# ATtiny2313A register map
Vendor: Atmel; File version: 1.0
CPU: other r0p0, little endian, no MPU, no FPU, 4 interrupt priority bits
Registers are 8-bit, read-write, reset 0x0 unless marked. A register's access mark holds for its fields unless they carry their own. Offsets are from the block's base; lines under a group give offsets from that group; [hi:lo] are bit positions; {n}, {i} and the like mark numbered series; 'fields as' and 'values as' point back to an identical list; <NAME> marks a mode.

## Memory map
0x00000000 FUSE size 0x3 — Fuses
0x00000000 LOCKBIT size 0x1 — Lockbits
0x00000021 AC blocks up to offset 0x8 — Analog Comparator
0x00000022 USART blocks up to offset 0xB
0x00000024 EXINT blocks up to offset 0x38 — External Interrupts
0x00000026 CPU blocks up to offset 0x38 — CPU Registers
0x0000002D USI size 0x3 — Universal Serial Interface
0x00000030 PORTD size 0x3 — I/O Port
0x00000036 PORTB size 0x3 — I/O Port
0x00000039 PORTA size 0x3 — I/O Port
0x0000003C EEPROM size 0x3
0x00000041 WDT size 0x1 — Watchdog Timer
0x00000042 TC1 blocks up to offset 0x18 — Timer/Counter, 16-bit
0x00000050 TC0 blocks up to offset 0xD — Timer/Counter, 8-bit

## Interrupts
0 RESET (CPU) — External Reset, Power-on Reset and Watchdog Reset
1 INT0 (CPU) — External Interrupt Request 0
2 INT1 (CPU) — External Interrupt Request 1
3 TIMER1_CAPT (CPU) — Timer/Counter1 Capture Event
4 TIMER1_COMPA (CPU) — Timer/Counter1 Compare Match A
5 TIMER1_OVF (CPU) — Timer/Counter1 Overflow
6 TIMER0_OVF (CPU) — Timer/Counter0 Overflow
7 USART_RX (CPU) — USART, Rx Complete
8 USART_UDRE (CPU) — USART Data Register Empty
9 USART_TX (CPU) — USART, Tx Complete
10 ANA_COMP (CPU) — Analog Comparator
11 PCINT_B (CPU) — Pin Change Interrupt Request B
12 TIMER1_COMPB (CPU)
13 TIMER0_COMPA (CPU)
14 TIMER0_COMPB (CPU)
15 USI_START (CPU) — USI Start Condition
16 USI_OVERFLOW (CPU)
17 EEPROM_Ready (CPU)
18 WDT_OVERFLOW (CPU) — Watchdog Timer Overflow
19 PCINT_A (CPU) — Pin Change Interrupt Request A
20 PCINT_D (CPU) — Pin Change Interrupt Request D

## AC — Analog Comparator
Base 0x00000021
0x00 DIDR — Digital Input Disable Register 1
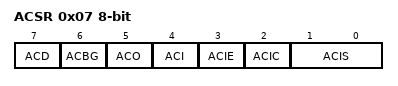
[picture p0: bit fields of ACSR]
0x07 ACSR — Analog Comparator Control And Status Register
  [7] ACD — Analog Comparator Disable
  [6] ACBG — Analog Comparator Bandgap Select
  [5] ACO — Analog Compare Output
  [4] ACI — Analog Comparator Interrupt Flag
  [3] ACIE — Analog Comparator Interrupt Enable
  [2] ACIC
  [1:0] ACIS — Analog Comparator Interrupt Mode Select bits
    0=Interrupt on Toggle; 2=Interrupt on Falling Edge; 3=Interrupt on Rising Edge

## CPU — CPU Registers
Base 0x00000026
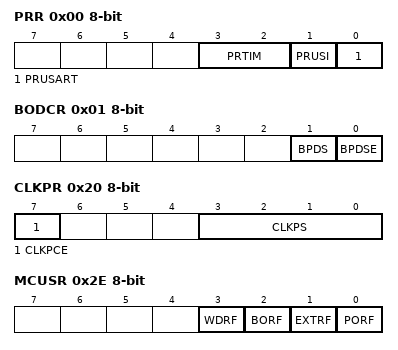
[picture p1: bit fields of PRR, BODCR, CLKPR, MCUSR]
0x00 PRR — Power reduction register
  [3:2] PRTIM, [1] PRUSI, [0] PRUSART
0x01 BODCR — BOD control register
  [1] BPDS, [0] BPDSE
{0xD+i} GPIOR{i} (i=0..2) — General Purpose I/O Register {i}
0x1D GTCCR — General Timer Counter Control Register
  [0] PSR10
0x20 CLKPR — Clock Prescale Register
  [7] CLKPCE — Clock Prescaler Change Enable
  [3:0] CLKPS — Clock Prescaler Select Bits
    0=1; 1=2; 2=4; 3=8; 4=16; 5=32; 6=64; 7=128; 8=256
0x2B OSCCAL — Oscillator Calibration Register
  [7:0] OSCCAL — Oscillator Calibration
0x2E MCUSR — MCU Status register
  [3] WDRF — Watchdog Reset Flag
  [2] BORF — Brown-out Reset Flag
  [1] EXTRF — External Reset Flag
  [0] PORF — Power-On Reset Flag
0x2F MCUCR — MCU Control Register
  [7] PUD — Pull-up Disable
  [5] SE — Sleep Enable
  [6:4] SM — Sleep Mode Select Bits
    0=IDLE; 1=PDOWN2 (Power Down); 4=STDBY (Standby); 5=PDOWN (Power Down)
  [3:2] ISC1 — Interrupt Sense Control 1 bits
    0=Low Level of INTX; 1=Any Logical Change in INTX; 2=Falling Edge of INTX; 3=Rising Edge of INTX
  [1:0] ISC0 — Interrupt Sense Control 0 bits
    values as ISC1
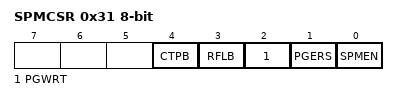
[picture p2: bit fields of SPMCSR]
0x31 SPMCSR — Store Program Memory Control and Status register
  [4] CTPB — Clear Temporary Page Buffer
  [3] RFLB — Read Fuse and Lock Bits
  [2] PGWRT — Page Write
  [1] PGERS — Page Erase
  [0] SPMEN — Store Program Memory Enable
0x37 SPL — Stack Pointer Low Byte
